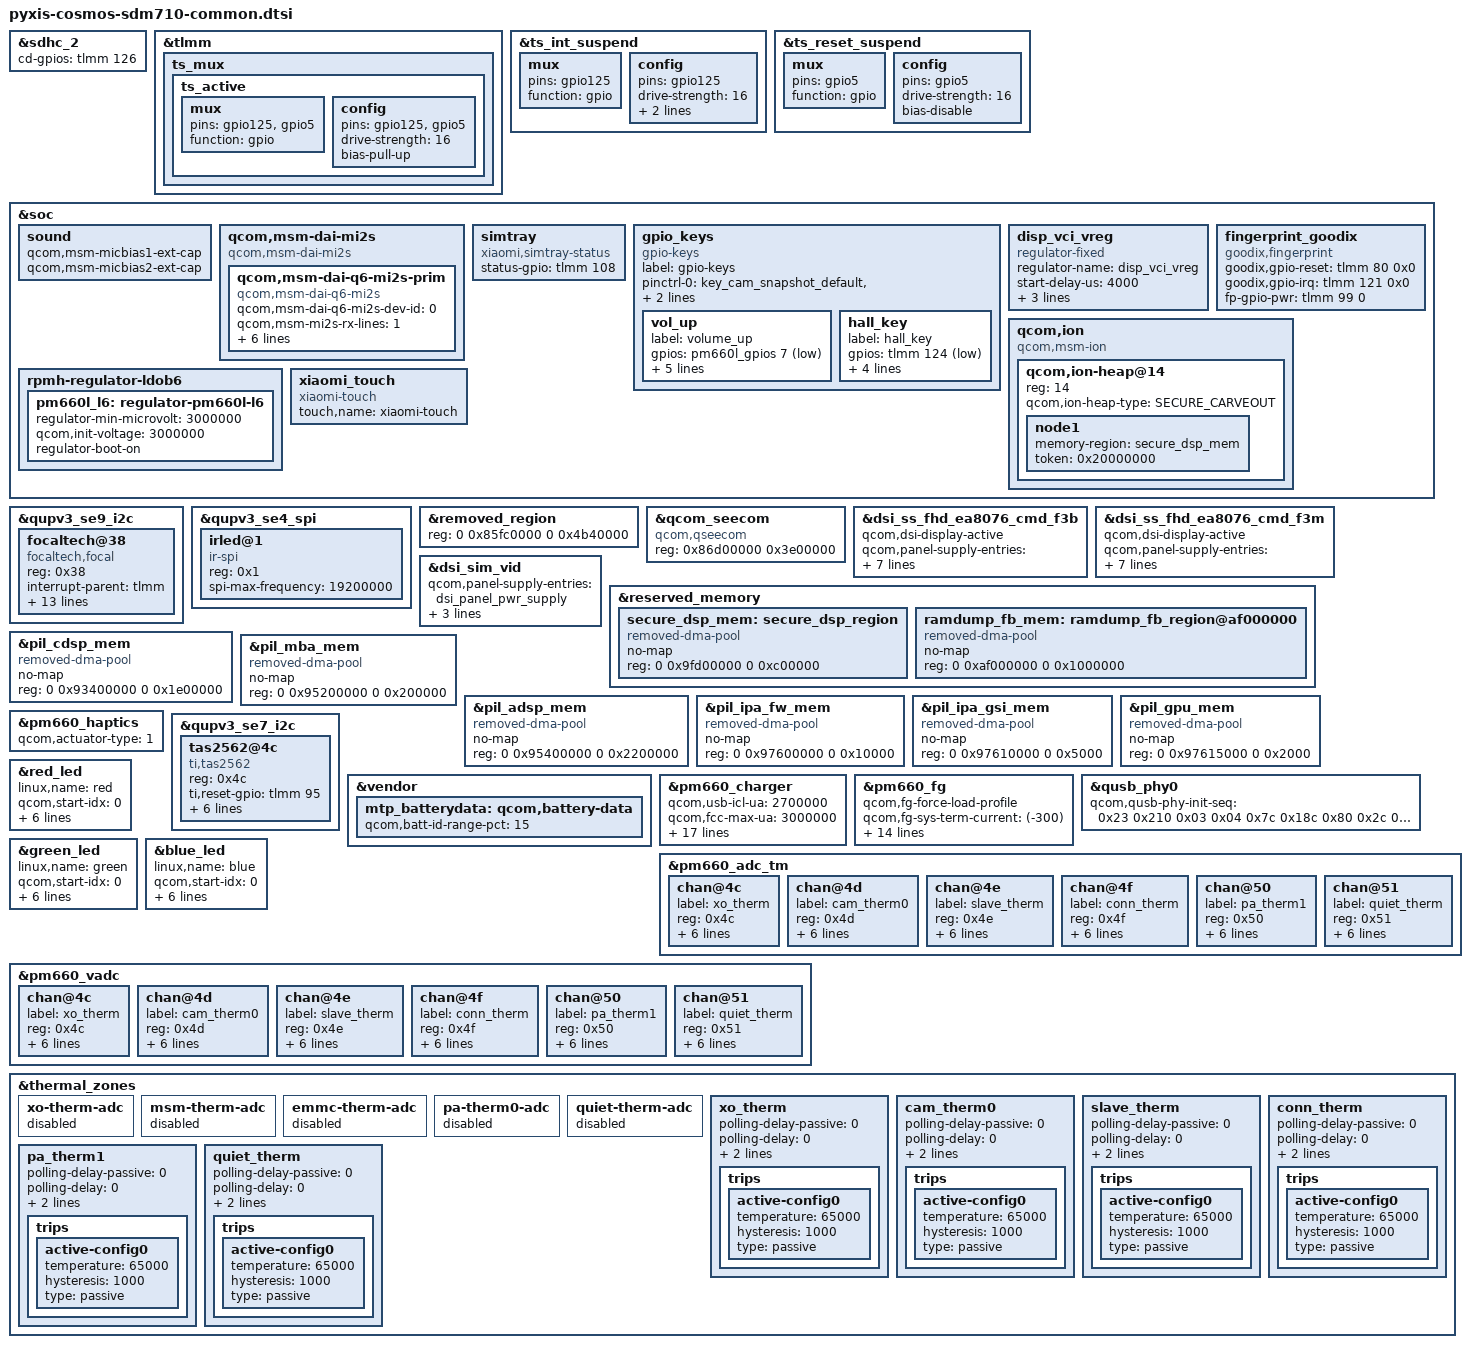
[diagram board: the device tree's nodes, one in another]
/* Copyright (c) 2018, The Linux Foundation. All rights reserved.
 * Copyright (C) 2019 XiaoMi, Inc.
 *
 * This program is free software; you can redistribute it and/or modify
 * it under the terms of the GNU General Public License version 2 and
 * only version 2 as published by the Free Software Foundation.
 *
 * This program is distributed in the hope that it will be useful,
 * but WITHOUT ANY WARRANTY; without even the implied warranty of
 * MERCHANTABILITY or FITNESS FOR A PARTICULAR PURPOSE.  See the
 * GNU General Public License for more details.
 */
#include "xiaomi-sdm710-common.dtsi"
#include "xiaomi-sde-display.dtsi"
#include "pyxis-sdm710-camera-sensor.dtsi"

&sdhc_2 {
	cd-gpios = <&tlmm 126 0x0>;
	status = "ok";
};

&tlmm {
	ts_mux {
		ts_active: ts_active {
			mux {
				pins = "gpio125", "gpio5";
				function = "gpio";
			};

			config {
				pins = "gpio125", "gpio5";
				drive-strength = <16>;
				bias-pull-up;
			};
		};
	};
};

&ts_int_suspend {
	mux {
		pins = "gpio125";
		function = "gpio";
	};

	config {
		pins = "gpio125";
		drive-strength = <16>;
		bias-diable;
		input-enable;
	};

};

&ts_reset_suspend {
	mux {
		pins = "gpio5";
		function = "gpio";
	};

	config {
		pins = "gpio5";
		drive-strength = <16>;
		bias-disable;
	};
};

&soc {
	sound {
		qcom,msm-micbias1-ext-cap;
		qcom,msm-micbias2-ext-cap;
	};

	qcom,msm-dai-mi2s {
		compatible = "qcom,msm-dai-mi2s";
		qcom,msm-dai-q6-mi2s-prim {
			compatible = "qcom,msm-dai-q6-mi2s";
			qcom,msm-dai-q6-mi2s-dev-id = <0>;
			qcom,msm-mi2s-rx-lines = <1>;
			qcom,msm-mi2s-tx-lines = <2>;
			pinctrl-names = "default", "sleep";
			pinctrl-0 = <&pri_mi2s_active
				&pri_mi2s_ws_active
				&pri_mi2s_sd0_active
				&pri_mi2s_sd1_active>;
			pinctrl-1 = <&pri_mi2s_sleep
				&pri_mi2s_ws_sleep
				&pri_mi2s_sd0_sleep
				&pri_mi2s_sd1_sleep>;
		};
	};

	simtray {
		compatible = "xiaomi,simtray-status";
		status-gpio = <&tlmm 108 0x00>;
	};
};

&qupv3_se9_i2c {
	status = "ok";
	focaltech@38 {
		compatible = "focaltech,focal";
		reg = <0x38>;
		interrupt-parent = <&tlmm>;
		interrupts = <125 0x2002>;
		vddio-supply = <&pm660_l13>;
		avdd-supply = <&pm660l_l8>;
		focaltech,avdd-load = <300000>;
		focaltech,reset-gpio = <&tlmm 5 0x01>;
		focaltech,irq-gpio = <&tlmm 125 0x02>;
		focaltech,max-touch-number = <10>;
		focaltech,display-coords = <0 0 1080 2340>;
		focaltech,reset-when-resume;
		focaltech,lockdown-info-addr = <0x1E000>;
		focaltech,open-min = <2700>;
		pinctrl-names = "pmx_ts_active", "pmx_ts_suspend";
		pinctrl-0 = <&ts_active>;
		pinctrl-1 = <&ts_int_suspend &ts_reset_suspend>;
		/* focaltech,have-key; */
	};

};

&qupv3_se4_spi {
	status = "ok";
	irled@1 {
		compatible = "ir-spi";
		reg = <0x1>;
		status = "ok";
		spi-max-frequency = <19200000>;
	};
};

&soc {
	gpio_keys {
		compatible = "gpio-keys";
		label = "gpio-keys";

		pinctrl-names = "default";
		pinctrl-0 = <&key_cam_snapshot_default
			    &key_cam_focus_default
			    &key_vol_up_default
			    &key_hall_default>;

		vol_up {
			label = "volume_up";
			gpios = <&pm660l_gpios 7 GPIO_ACTIVE_LOW>;
			linux,input-type = <1>;
			linux,code = <115>;
			gpio-key,wakeup;
			debounce-interval = <15>;
			linux,can-disable;
		};
		hall_key {
			label = "hall_key";
			gpios = <&tlmm 124 GPIO_ACTIVE_LOW>;
			linux,input-type = <5>;
			linux,code = <0>;
			gpio-key,wakeup;
			debounce-interval = <15>;
		};
	};

	disp_vci_vreg: disp_vci_vreg {
		compatible = "regulator-fixed";
		regulator-name = "disp_vci_vreg";
		start-delay-us = <4000>;
		enable-active-high;
		regulator-boot-on;
		gpio = <&tlmm 76 0>;
	};

	fingerprint_goodix {
		compatible = "goodix,fingerprint";
		goodix,gpio-reset = <&tlmm 80 0x0>;
		goodix,gpio-irq = <&tlmm 121 0x0>;
		fp-gpio-pwr = <&tlmm 99 0>;
		status = "ok";
	};

	qcom,ion {
		compatible = "qcom,msm-ion";
		#address-cells = <1>;
		#size-cells = <0>;

		qcom,ion-heap@14 {
			reg = <14>;
			qcom,ion-heap-type = "SECURE_CARVEOUT";
			node1 {
				memory-region = <&secure_dsp_mem>;
				token = <0x20000000>; /* ION_FLAG_CP_CDSP */
			};
		};
	};

	rpmh-regulator-ldob6 {
		pm660l_l6: regulator-pm660l-l6 {
			regulator-min-microvolt = <3000000>;
			qcom,init-voltage = <3000000>;
			regulator-boot-on;
			/*regulator-always-on;*/
		};
	};

	xiaomi_touch {
		compatible = "xiaomi-touch";
		status = "ok";
		touch,name = "xiaomi-touch";
	};

};

&removed_region {
	reg = <0 0x85fc0000 0 0x4b40000>;
};

&qcom_seecom {
	compatible = "qcom,qseecom";
	reg = <0x86d00000 0x3e00000>;
};

&dsi_ss_fhd_ea8076_cmd_f3b {
	qcom,dsi-display-active;
	qcom,panel-supply-entries = <&dsi_amoled_panel_pwr_supply>;
	qcom,mdss-dsi-bl-pmic-control-type = "bl_ctrl_dcs";
	qcom,mdss-dsi-bl-min-level = <2>;
	qcom,mdss-dsi-bl-max-level = <2047>;
	qcom,platform-reset-gpio = <&tlmm 75 0>;
	qcom,platform-te-gpio = <&tlmm 10 0>;
};

&dsi_ss_fhd_ea8076_cmd_f3m {
	qcom,dsi-display-active;
	qcom,panel-supply-entries = <&dsi_amoled_panel_pwr_supply>;
	qcom,mdss-dsi-bl-pmic-control-type = "bl_ctrl_dcs";
	qcom,mdss-dsi-bl-min-level = <2>;
	qcom,mdss-dsi-bl-max-level = <2047>;
	qcom,platform-reset-gpio = <&tlmm 75 0>;
	qcom,platform-te-gpio = <&tlmm 10 0>;
};

&dsi_sim_vid {
	qcom,panel-supply-entries = <&dsi_panel_pwr_supply>;
	qcom,mdss-dsi-bl-pmic-control-type = "bl_ctrl_dcs";
	qcom,platform-reset-gpio = <&tlmm 75 0>;
};

&reserved_memory {
	secure_dsp_mem: secure_dsp_region {
		compatible = "removed-dma-pool";
		no-map;
		reg = <0 0x9fd00000 0 0xc00000>;
	};

	ramdump_fb_mem: ramdump_fb_region@af000000 {
		compatible = "removed-dma-pool";
		no-map;
		reg = <0 0xaf000000 0 0x1000000>;
	};
};


&pil_cdsp_mem {
	compatible = "removed-dma-pool";
	no-map;
	reg = <0 0x93400000 0 0x1e00000>;
};

&pil_mba_mem {
	compatible = "removed-dma-pool";
	no-map;
	reg = <0 0x95200000 0 0x200000>;
};

&pil_adsp_mem {
	compatible = "removed-dma-pool";
	no-map;
	reg = <0 0x95400000 0 0x2200000>;
};

&pil_ipa_fw_mem {
	compatible = "removed-dma-pool";
	no-map;
	reg = <0 0x97600000 0 0x10000>;
};

&pil_ipa_gsi_mem {
	compatible = "removed-dma-pool";
	no-map;
	reg = <0 0x97610000 0 0x5000>;
};

&pil_gpu_mem {
	compatible = "removed-dma-pool";
	no-map;
	reg = <0 0x97615000 0 0x2000>;
};

&pm660_haptics {
	qcom,actuator-type = <1>;
	status = "okay";
};


&qupv3_se7_i2c {
	status = "ok";
	tas2562@4c {
		compatible = "ti,tas2562";
		reg = <0x4c>;
		ti,reset-gpio = <&tlmm 95 0>;
		ti,irq-gpio = <&tlmm 96 0>;
		ti,asi-format = <0>; /* 0, i2S; 1, DSP;  */
		ti,left-slot = <0>; /* <left slot number> */
		ti,right-slot = <1>; /* <right slot number> */
		ti,imon-slot-no = <0>; /* <current sense slot number> */
		ti,vmon-slot-no = <2>; /* <current voltage slot number> */
		status = "ok";
	};
};


&vendor {
	mtp_batterydata: qcom,battery-data {
		qcom,batt-id-range-pct = <15>;
		#include "batterydata-f3b-sunwoda-4030mAh.dtsi"
		#include "batterydata-f3b-scud-4030mAh.dtsi"
	};
};

&pm660_charger {
	qcom,usb-icl-ua = <2700000>;
	qcom,fcc-max-ua = <3000000>;
	qcom,fcc-low-temp-delta = <2700000>;
	qcom,fcc-hot-temp-delta = <1500000>;
	qcom,fcc-cool-temp-delta = <2100000>;
	qcom,auto-recharge-soc;
	qcom,sw-jeita-enable;
	qcom,dynamic-fv-enable;
	support_hw_scpcharger;
	qcom,thermal-mitigation
				= <1800000 1600000 1400000 1200000 1000000 1000000 1000000>;
	qcom,thermal-mitigation-dcp
				= <1800000 1800000 1800000 1800000 1800000 1800000 1800000
				1800000 1800000 1800000 1800000 1800000 1600000 1400000
				1200000 1000000>;
	qcom,thermal-mitigation-qc3
				= <2700000 2625000 2575000 2425000 2275000 2125000 2000000
				1800000 1650000 1500000 1360000 1200000 1060000 900000
				752500 525000>;
	qcom,thermal-mitigation-qc2
				= <1625000 1625000 1625000 1625000 1625000 1525000 1425000
				1325000 1225000 1125000 10255000 925000 825000 725000
				625000 525000>;
	qcom,thermal-mitigation-pd-base
				= <3000000 2800000 2600000 2400000 2200000 2000000 1800000
				1600000 1600000 1400000 1200000 1100000 1000000 900000
				752500 525000>;
};

&pm660_fg {
	qcom,fg-force-load-profile;
	qcom,fg-sys-term-current = <(-300)>;
	qcom,fg-chg-term-current = <200>;
	qcom,fg-auto-recharge-soc;
	qcom,fg-recharge-soc-thr = <99>;
	qcom,fg-cutoff-voltage = <3400>;
	qcom,fg-empty-voltage = <3100>;
	qcom,fg-cutoff-current = <200>;
	qcom,fg-jeita-hyst-temp = <1>;
	qcom,fg-jeita-thresholds = <0 15 45 59>;
	qcom,fg-esr-clamp-mohms = <60>;
	qcom,fg-batt-temp-delta = <6>;
	qcom,slope-limit-temp-threshold = <100>;
	qcom,slope-limit-coeffs = <10 11 12 13>;
	qcom,battery-thermal-coefficients = [d2 50 ff];
	qcom,battery-data = <&mtp_batterydata>;
};

&qusb_phy0 {
	qcom,qusb-phy-init-seq =
		/* <value reg_offset> */
		<0x23 0x210 /* PWR_CTRL1 */
		0x03 0x04  /* PLL_ANALOG_CONTROLS_TWO */
		0x7c 0x18c /* PLL_CLOCK_INVERTERS */
		0x80 0x2c  /* PLL_CMODE */
		0x0a 0x184 /* PLL_LOCK_DELAY */
		0x19 0xb4  /* PLL_DIGITAL_TIMERS_TWO */
		0x40 0x194 /* PLL_BIAS_CONTROL_1 */
		0x24 0x198 /* PLL_BIAS_CONTROL_2 */
		0x21 0x214 /* PWR_CTRL2 */
		0x08 0x220 /* IMP_CTRL1 */
		0x58 0x224 /* IMP_CTRL2 */
		0x07 0x240 /* TUNE1 */
		0x2b 0x244 /* TUNE2 */
		0xca 0x248 /* TUNE3 */
		0x04 0x24c /* TUNE4 */
		0x03 0x250 /* TUNE5 */
		0x00 0x23c /* CHG_CTRL2 */
		0x22 0x210>; /* PWR_CTRL1 */
};

&red_led {
	linux,name = "red";
	qcom,start-idx = <0>;
	qcom,idx-len = <46>;
	qcom,duty-pcts =
		[00 00 01 02 04 06 08 0B 0D 11 14 17 1B 1E 21 25 27 2A 2C 2E 30 31 32
		32 32 31 30 2E 2C 2A 27 25 21 1E 1B 17 14 11 0D 0B 08 06 04 02 01 00];
	qcom,ramp-step-ms = <73>;
	qcom,pause-lo = <10>;
	qcom,use-blink;
};

&green_led {
	linux,name = "green";
	qcom,start-idx = <0>;
	qcom,idx-len = <46>;
	qcom,duty-pcts =
		[00 00 01 02 04 06 08 0B 0D 11 14 17 1B 1E 21 25 27 2A 2C 2E 30 31 32
		32 32 31 30 2E 2C 2A 27 25 21 1E 1B 17 14 11 0D 0B 08 06 04 02 01 00];
	qcom,ramp-step-ms = <73>;
	qcom,pause-lo = <10>;
	qcom,use-blink;
};

&blue_led {
	linux,name = "blue";
	qcom,start-idx = <0>;
	qcom,idx-len = <46>;
	qcom,duty-pcts =
		[00 00 01 02 04 06 08 0B 0D 11 14 17 1B 1E 21 25 27 2A 2C 2E 30 31 32
		32 32 31 30 2E 2C 2A 27 25 21 1E 1B 17 14 11 0D 0B 08 06 04 02 01 00];
	qcom,ramp-step-ms = <73>;
	qcom,pause-lo = <10>;
	qcom,use-blink;
};

&pm660_haptics {
	qcom,actuator-type = <1>;
	status = "okay";
};

&pm660_adc_tm {
	chan@4c {
		label = "xo_therm";
		reg = <0x4c>;
		qcom,pre-div-channel-scaling = <0>;
		qcom,calibration-type = "ratiometric";
		qcom,scale-function = <4>;
		qcom,hw-settle-time = <2>;
		qcom,btm-channel-number = <0x78>;
		qcom,thermal-node;
	};

	chan@4d {
		label = "cam_therm0";
		reg = <0x4d>;
		qcom,pre-div-channel-scaling = <0>;
		qcom,calibration-type = "ratiometric";
		qcom,scale-function = <2>;
		qcom,hw-settle-time = <2>;
		qcom,btm-channel-number = <0x68>;
		qcom,thermal-node;
	};

	chan@4e {
		label = "slave_therm";
		reg = <0x4e>;
		qcom,pre-div-channel-scaling = <0>;
		qcom,calibration-type = "ratiometric";
		qcom,scale-function = <2>;
		qcom,hw-settle-time = <2>;
		qcom,btm-channel-number = <0x80>;
		qcom,thermal-node;
	};

	chan@4f {
		label = "conn_therm";
		reg = <0x4f>;
		qcom,pre-div-channel-scaling = <0>;
		qcom,calibration-type = "ratiometric";
		qcom,scale-function = <2>;
		qcom,hw-settle-time = <2>;
		qcom,btm-channel-number = <0x88>;
		qcom,thermal-node;
	};

	chan@50 {
		label = "pa_therm1";
		reg = <0x50>;
		qcom,pre-div-channel-scaling = <0>;
		qcom,calibration-type = "ratiometric";
		qcom,scale-function = <2>;
		qcom,hw-settle-time = <2>;
		qcom,btm-channel-number = <0x90>;
		qcom,thermal-node;
	};

	chan@51 {
		label = "quiet_therm";
		reg = <0x51>;
		qcom,pre-div-channel-scaling = <0>;
		qcom,calibration-type = "ratiometric";
		qcom,scale-function = <2>;
		qcom,hw-settle-time = <2>;
		qcom,btm-channel-number = <0x70>;
		qcom,thermal-node;
	};
};

&pm660_vadc {
	chan@4c {
		label = "xo_therm";
		reg = <0x4c>;
		qcom,decimation = <2>;
		qcom,pre-div-channel-scaling = <0>;
		qcom,calibration-type = "ratiometric";
		qcom,scale-function = <4>;
		qcom,hw-settle-time = <2>;
		qcom,fast-avg-setup = <0>;
	};

	chan@4d {
		label = "cam_therm0";
		reg = <0x4d>;
		qcom,decimation = <2>;
		qcom,pre-div-channel-scaling = <0>;
		qcom,calibration-type = "ratiometric";
		qcom,scale-function = <2>;
		qcom,hw-settle-time = <2>;
		qcom,fast-avg-setup = <0>;
	};

	chan@4e {
		label = "slave_therm";
		reg = <0x4e>;
		qcom,decimation = <2>;
		qcom,pre-div-channel-scaling = <0>;
		qcom,calibration-type = "ratiometric";
		qcom,scale-function = <2>;
		qcom,hw-settle-time = <2>;
		qcom,fast-avg-setup = <0>;
	};

	chan@4f {
		label = "conn_therm";
		reg = <0x4f>;
		qcom,decimation = <2>;
		qcom,pre-div-channel-scaling = <0>;
		qcom,calibration-type = "ratiometric";
		qcom,scale-function = <2>;
		qcom,hw-settle-time = <2>;
		qcom,fast-avg-setup = <0>;
	};

	chan@50 {
		label = "pa_therm1";
		reg = <0x50>;
		qcom,decimation = <2>;
		qcom,pre-div-channel-scaling = <0>;
		qcom,calibration-type = "ratiometric";
		qcom,scale-function = <2>;
		qcom,hw-settle-time = <2>;
		qcom,fast-avg-setup = <0>;
	};

	chan@51 {
		label = "quiet_therm";
		reg = <0x51>;
		qcom,decimation = <2>;
		qcom,pre-div-channel-scaling = <0>;
		qcom,calibration-type = "ratiometric";
		qcom,scale-function = <2>;
		qcom,hw-settle-time = <2>;
		qcom,fast-avg-setup = <0>;
	};
};

&thermal_zones {
	xo-therm-adc {
		status = "disabled";
	};

	msm-therm-adc {
		status = "disabled";
	};

	emmc-therm-adc {
		status = "disabled";
	};

	pa-therm0-adc {
		status = "disabled";
	};

	quiet-therm-adc {
		status = "disabled";
	};

	xo_therm {
		polling-delay-passive = <0>;
		polling-delay = <0>;
		thermal-sensors = <&pm660_adc_tm 0x4c>;
		thermal-governor = "user_space";

		trips {
			active-config0 {
				temperature = <65000>;
				hysteresis = <1000>;
				type = "passive";
			};
		};
	};

	cam_therm0 {
		polling-delay-passive = <0>;
		polling-delay = <0>;
		thermal-sensors = <&pm660_adc_tm 0x4d>;
		thermal-governor = "user_space";

		trips {
			active-config0 {
				temperature = <65000>;
				hysteresis = <1000>;
				type = "passive";
			};
		};
	};

	slave_therm {
		polling-delay-passive = <0>;
		polling-delay = <0>;
		thermal-sensors = <&pm660_adc_tm 0x4e>;
		thermal-governor = "user_space";

		trips {
			active-config0 {
				temperature = <65000>;
				hysteresis = <1000>;
				type = "passive";
			};
		};
	};

	conn_therm {
		polling-delay-passive = <0>;
		polling-delay = <0>;
		thermal-sensors = <&pm660_adc_tm 0x4f>;
		thermal-governor = "user_space";

		trips {
			active-config0 {
				temperature = <65000>;
				hysteresis = <1000>;
				type = "passive";
			};
		};
	};

	pa_therm1 {
		polling-delay-passive = <0>;
		polling-delay = <0>;
		thermal-sensors = <&pm660_adc_tm 0x50>;
		thermal-governor = "user_space";

		trips {
			active-config0 {
				temperature = <65000>;
				hysteresis = <1000>;
				type = "passive";
			};
		};
	};

	quiet_therm {
		polling-delay-passive = <0>;
		polling-delay = <0>;
		thermal-sensors = <&pm660_adc_tm 0x51>;
		thermal-governor = "user_space";

		trips {
			active-config0 {
				temperature = <65000>;
				hysteresis = <1000>;
				type = "passive";
			};
		};
	};
};

